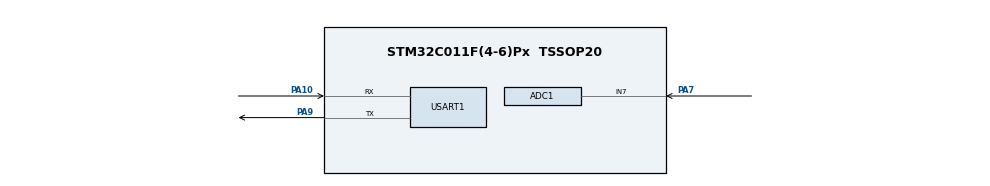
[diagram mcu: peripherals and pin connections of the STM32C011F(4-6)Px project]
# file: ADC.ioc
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ADC1.Channel-0\#ChannelRegularConversion=ADC_CHANNEL_7
ADC1.ContinuousConvMode=ENABLE
ADC1.DMAContinuousRequests=ENABLE
ADC1.NbrOfConversionFlag=1
ADC1.Rank-0\#ChannelRegularConversion=1
ADC1.SamplingTime-0\#ChannelRegularConversion=ADC_SAMPLINGTIME_COMMON_1
ADC1.SelectedChannel=ADC_CHANNEL_7
ADC1.master=1
Dma.ADC1.0.Direction=DMA_PERIPH_TO_MEMORY
Dma.ADC1.0.EventEnable=DISABLE
Dma.ADC1.0.Instance=DMA1_Channel1
Dma.ADC1.0.MemDataAlignment=DMA_MDATAALIGN_HALFWORD
Dma.ADC1.0.MemInc=DMA_MINC_ENABLE
Dma.ADC1.0.Mode=DMA_NORMAL
Dma.ADC1.0.PeriphDataAlignment=DMA_PDATAALIGN_HALFWORD
Dma.ADC1.0.PeriphInc=DMA_PINC_DISABLE
Dma.ADC1.0.Polarity=HAL_DMAMUX_REQ_GEN_RISING
Dma.ADC1.0.Priority=DMA_PRIORITY_LOW
Dma.ADC1.0.RequestNumber=1
Dma.ADC1.0.SignalID=NONE
Dma.ADC1.0.SyncEnable=DISABLE
Dma.ADC1.0.SyncPolarity=HAL_DMAMUX_SYNC_NO_EVENT
Dma.ADC1.0.SyncRequestNumber=1
Dma.ADC1.0.SyncSignalID=NONE
Dma.Request0=ADC1
Mcu.Family=STM32C0
Mcu.Name=STM32C011F(4-6)Px
Mcu.Package=TSSOP20
NVIC.ADC1_IRQn=true\:0\:0\:false\:false\:true\:true\:true\:true
NVIC.DMA1_Channel1_IRQn=true\:0\:0\:false\:false\:true\:false\:true\:true
PA10\ [PA12].Mode=Asynchronous
PA10\ [PA12].Signal=USART1_RX
PA13.Mode=Serial_Wire
PA13.Signal=DEBUG_SWDIO
PA14-BOOT0.Mode=Serial_Wire
PA14-BOOT0.Signal=DEBUG_SWCLK
PA7.Mode=IN7
PA7.Signal=ADC1_IN7
PA9\ [PA11].Mode=Asynchronous
PA9\ [PA11].Signal=USART1_TX
ProjectManager.HeapSize=0x200
ProjectManager.StackSize=0x400
ProjectManager.TargetToolchain=STM32CubeIDE
RCC.ADCFreq_Value=48000000
RCC.AHBFreq_Value=48000000
RCC.CortexFreq_Value=48000000
RCC.EXTERNAL_CLOCK_VALUE=12288000
RCC.HCLKFreq_Value=48000000
RCC.HSE_VALUE=8000000
RCC.HSISYSCLKDivider=RCC_HSI_DIV1
RCC.HSI_VALUE=48000000
RCC.LSE_VALUE=32768
RCC.SYSCLKFreq_VALUE=48000000
TIM3.Period=1000-1
TIM3.Prescaler=48000-1
USART1.VirtualMode-Asynchronous=VM_ASYNC
VP_SYS_VS_PINREMAP.Mode=PINREMAP
VP_SYS_VS_PINREMAP_10_12.Mode=PINREMAP_10_12
VP_TIM3_VS_ClockSourceINT.Mode=Internal
board=custom

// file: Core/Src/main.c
/* USER CODE BEGIN Header */
/**
  ******************************************************************************
  * @file           : main.c
  * @brief          : Main program body
  ******************************************************************************
  * @attention
  *
  * Copyright (c) 2024 STMicroelectronics.
  * All rights reserved.
  *
  * This software is licensed under terms that can be found in the LICENSE file
  * in the root directory of this software component.
  * If no LICENSE file comes with this software, it is provided AS-IS.
  *
  ******************************************************************************
  */
/* USER CODE END Header */
#include "main.h"

/* USER CODE BEGIN Includes */
#include "stdio.h"
#include "string.h"
/* USER CODE END Includes */

ADC_HandleTypeDef hadc1;
DMA_HandleTypeDef hdma_adc1;

TIM_HandleTypeDef htim3;

UART_HandleTypeDef huart1;

void SystemClock_Config(void);
static void MX_GPIO_Init(void);
static void MX_DMA_Init(void);
static void MX_USART1_UART_Init(void);
static void MX_ADC1_Init(void);
static void MX_TIM3_Init(void);

/* USER CODE BEGIN 0 */

// funcao dma
uint16_t adc_data[1];
void HAL_ADC_ConvCpltCallback(ADC_HandleTypeDef* hadc) {
	HAL_ADC_Stop_DMA(&hadc1);
    if (hadc->Instance == ADC1) { // Verifica se o callback é do ADC1
        char msg[50];
        // Formata a mensagem com os valores lidos do ADC
        sprintf(msg, "Leitura Potenciometro com DMA: %u\r\n", adc_data[0]);
        // Envia a mensagem pela UART
        HAL_UART_Transmit(&huart1, (uint8_t *)msg, strlen(msg), 1000);
    }
}
/*
// funcao de interrupcao
void HAL_ADC_ConvCpltCallback(ADC_HandleTypeDef *hadc) {
   uint32_t leituraPotenciometro = HAL_ADC_GetValue(&hadc1);
   char msg[50];
   sprintf(msg, "Leitura Potenciometro com Interrupcao: %lu\r\n", leituraPotenciometro); // Formata mensagem
   HAL_UART_Transmit(&huart1, (uint8_t *)msg, strlen(msg), 1000); // Imprime Serial
}*/

/* USER CODE END 0 */

int main(void)
{

  /* MCU Configuration--------------------------------------------------------*/

  /* Reset of all peripherals, Initializes the Flash interface and the Systick. */
  HAL_Init();

  /* Configure the system clock */
  SystemClock_Config();

  /* Initialize all configured peripherals */
  MX_GPIO_Init();
  MX_DMA_Init();
  MX_USART1_UART_Init();
  MX_ADC1_Init();
  MX_TIM3_Init();
  /* USER CODE BEGIN 2 */
  HAL_TIM_Base_Start(&htim3); // Inicia contagem
  HAL_ADCEx_Calibration_Start(&hadc1); // Rotina de calibração do ADC
  //HAL_ADC_Start_IT(&hadc1);
  /* USER CODE END 2 */

  /* Infinite loop */
  while (1)
  {

    /* USER CODE BEGIN 3 */
   HAL_ADC_Start_DMA(&hadc1, (uint32_t *)adc_data, 1);

	/*
   if(__HAL_TIM_GET_FLAG(&htim3, TIM_FLAG_UPDATE)){
	   __HAL_TIM_CLEAR_FLAG(&htim3, TIM_FLAG_UPDATE);
	   // ADC Polling
	   HAL_ADC_Start (&hadc1);   // inicia leitura ADC
	   HAL_ADC_PollForConversion (&hadc1, 1000); //aguarda conversao seja concluida
	   uint32_t leituraPotenciometro = HAL_ADC_GetValue (&hadc1); //  ler valor analogico
	   HAL_ADC_Stop(&hadc1);
	   char msg[50];
	   sprintf(msg, "Leitura Potenciometro: %lu\r\n", leituraPotenciometro); // Formata mensagem
	   HAL_UART_Transmit(&huart1, (uint8_t *)msg, strlen(msg), 1000); // Imprime Serial
	}*/

  }
  /* USER CODE END 3 */
}

void SystemClock_Config(void)
{
  RCC_OscInitTypeDef RCC_OscInitStruct = {0};
  RCC_ClkInitTypeDef RCC_ClkInitStruct = {0};

  /** Initializes the RCC Oscillators according to the specified parameters
  * in the RCC_OscInitTypeDef structure.
  */
  RCC_OscInitStruct.OscillatorType = RCC_OSCILLATORTYPE_HSI;
  RCC_OscInitStruct.HSIState = RCC_HSI_ON;
  RCC_OscInitStruct.HSIDiv = RCC_HSI_DIV1;
  RCC_OscInitStruct.HSICalibrationValue = RCC_HSICALIBRATION_DEFAULT;
  if (HAL_RCC_OscConfig(&RCC_OscInitStruct) != HAL_OK)
  {
    Error_Handler();
  }

  /** Initializes the CPU, AHB and APB buses clocks
  */
  RCC_ClkInitStruct.ClockType = RCC_CLOCKTYPE_HCLK|RCC_CLOCKTYPE_SYSCLK
                              |RCC_CLOCKTYPE_PCLK1;
  RCC_ClkInitStruct.SYSCLKSource = RCC_SYSCLKSOURCE_HSI;
  RCC_ClkInitStruct.SYSCLKDivider = RCC_SYSCLK_DIV1;
  RCC_ClkInitStruct.AHBCLKDivider = RCC_HCLK_DIV1;
  RCC_ClkInitStruct.APB1CLKDivider = RCC_APB1_DIV1;

  if (HAL_RCC_ClockConfig(&RCC_ClkInitStruct, FLASH_LATENCY_1) != HAL_OK)
  {
    Error_Handler();
  }
}

static void MX_ADC1_Init(void)
{

  ADC_ChannelConfTypeDef sConfig = {0};

  /** Configure the global features of the ADC (Clock, Resolution, Data Alignment and number of conversion)
  */
  hadc1.Instance = ADC1;
  hadc1.Init.ClockPrescaler = ADC_CLOCK_SYNC_PCLK_DIV2;
  hadc1.Init.Resolution = ADC_RESOLUTION_12B;
  hadc1.Init.DataAlign = ADC_DATAALIGN_RIGHT;
  hadc1.Init.ScanConvMode = ADC_SCAN_DISABLE;
  hadc1.Init.EOCSelection = ADC_EOC_SINGLE_CONV;
  hadc1.Init.LowPowerAutoWait = DISABLE;
  hadc1.Init.LowPowerAutoPowerOff = DISABLE;
  hadc1.Init.ContinuousConvMode = ENABLE;
  hadc1.Init.NbrOfConversion = 1;
  hadc1.Init.ExternalTrigConv = ADC_SOFTWARE_START;
  hadc1.Init.ExternalTrigConvEdge = ADC_EXTERNALTRIGCONVEDGE_NONE;
  hadc1.Init.DMAContinuousRequests = ENABLE;
  hadc1.Init.Overrun = ADC_OVR_DATA_PRESERVED;
  hadc1.Init.SamplingTimeCommon1 = ADC_SAMPLETIME_1CYCLE_5;
  hadc1.Init.SamplingTimeCommon2 = ADC_SAMPLETIME_1CYCLE_5;
  hadc1.Init.OversamplingMode = DISABLE;
  hadc1.Init.TriggerFrequencyMode = ADC_TRIGGER_FREQ_HIGH;
  if (HAL_ADC_Init(&hadc1) != HAL_OK)
  {
    Error_Handler();
  }

  /** Configure Regular Channel
  */
  sConfig.Channel = ADC_CHANNEL_7;
  sConfig.Rank = ADC_REGULAR_RANK_1;
  sConfig.SamplingTime = ADC_SAMPLINGTIME_COMMON_1;
  if (HAL_ADC_ConfigChannel(&hadc1, &sConfig) != HAL_OK)
  {
    Error_Handler();
  }

}

static void MX_TIM3_Init(void)
{

  TIM_ClockConfigTypeDef sClockSourceConfig = {0};
  TIM_MasterConfigTypeDef sMasterConfig = {0};

  htim3.Instance = TIM3;
  htim3.Init.Prescaler = 48000-1;
  htim3.Init.CounterMode = TIM_COUNTERMODE_UP;
  htim3.Init.Period = 1000-1;
  htim3.Init.ClockDivision = TIM_CLOCKDIVISION_DIV1;
  htim3.Init.AutoReloadPreload = TIM_AUTORELOAD_PRELOAD_DISABLE;
  if (HAL_TIM_Base_Init(&htim3) != HAL_OK)
  {
    Error_Handler();
  }
  sClockSourceConfig.ClockSource = TIM_CLOCKSOURCE_INTERNAL;
  if (HAL_TIM_ConfigClockSource(&htim3, &sClockSourceConfig) != HAL_OK)
  {
    Error_Handler();
  }
  sMasterConfig.MasterOutputTrigger = TIM_TRGO_RESET;
  sMasterConfig.MasterSlaveMode = TIM_MASTERSLAVEMODE_DISABLE;
  if (HAL_TIMEx_MasterConfigSynchronization(&htim3, &sMasterConfig) != HAL_OK)
  {
    Error_Handler();
  }

}

static void MX_USART1_UART_Init(void)
{

  huart1.Instance = USART1;
  huart1.Init.BaudRate = 115200;
  huart1.Init.WordLength = UART_WORDLENGTH_8B;
  huart1.Init.StopBits = UART_STOPBITS_1;
  huart1.Init.Parity = UART_PARITY_NONE;
  huart1.Init.Mode = UART_MODE_TX_RX;
  huart1.Init.HwFlowCtl = UART_HWCONTROL_NONE;
  huart1.Init.OverSampling = UART_OVERSAMPLING_16;
  huart1.Init.OneBitSampling = UART_ONE_BIT_SAMPLE_DISABLE;
  huart1.Init.ClockPrescaler = UART_PRESCALER_DIV1;
  huart1.AdvancedInit.AdvFeatureInit = UART_ADVFEATURE_NO_INIT;
  if (HAL_UART_Init(&huart1) != HAL_OK)
  {
    Error_Handler();
  }
  if (HAL_UARTEx_SetTxFifoThreshold(&huart1, UART_TXFIFO_THRESHOLD_1_8) != HAL_OK)
  {
    Error_Handler();
  }
  if (HAL_UARTEx_SetRxFifoThreshold(&huart1, UART_RXFIFO_THRESHOLD_1_8) != HAL_OK)
  {
    Error_Handler();
  }
  if (HAL_UARTEx_DisableFifoMode(&huart1) != HAL_OK)
  {
    Error_Handler();
  }

}

static void MX_DMA_Init(void)
{

  /* DMA controller clock enable */
  __HAL_RCC_DMA1_CLK_ENABLE();

  /* DMA interrupt init */
  /* DMA1_Channel1_IRQn interrupt configuration */
  HAL_NVIC_SetPriority(DMA1_Channel1_IRQn, 0, 0);
  HAL_NVIC_EnableIRQ(DMA1_Channel1_IRQn);

}

static void MX_GPIO_Init(void)
{

  /* GPIO Ports Clock Enable */
  __HAL_RCC_GPIOA_CLK_ENABLE();

}

void Error_Handler(void)
{
  __disable_irq();
  while (1)
  {
  }
}
